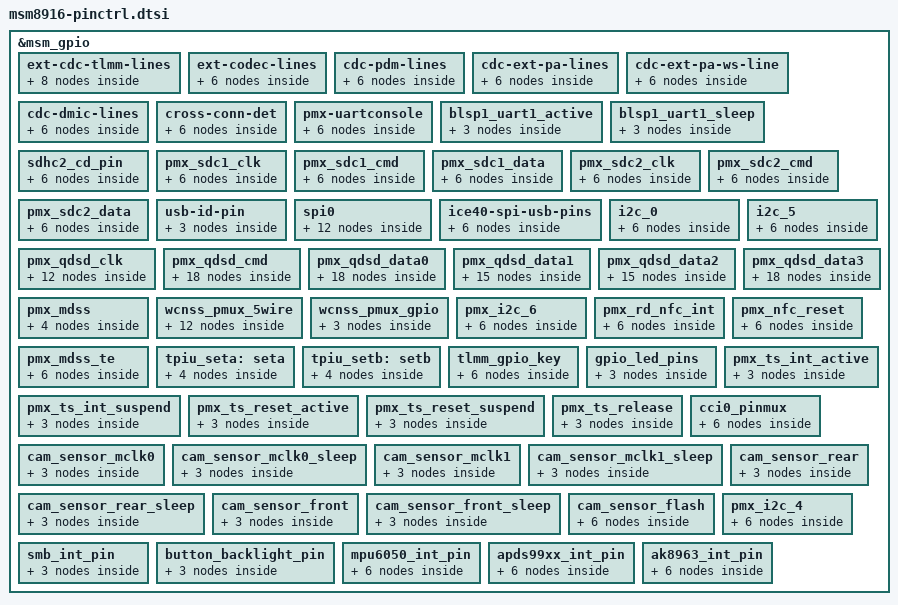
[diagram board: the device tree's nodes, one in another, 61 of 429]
/* Copyright (c) 2013-2014, The Linux Foundation. All rights reserved.
 *
 * This program is free software; you can redistribute it and/or modify
 * it under the terms of the GNU General Public License version 2 and
 * only version 2 as published by the Free Software Foundation.
 *
 * This program is distributed in the hope that it will be useful,
 * but WITHOUT ANY WARRANTY; without even the implied warranty of
 * MERCHANTABILITY or FITNESS FOR A PARTICULAR PURPOSE.  See the
 * GNU General Public License for more details.
 */

&msm_gpio {
	ext-cdc-tlmm-lines {
		ext_cdc_tlmm_lines_act: tlmm_lines_on {
			pinmux_pri {
				function = "pri_mi2s";
				pins = "gpio116";
			};
			pinmux_sec {
				function = "sec_mi2s";
				pins = "gpio112", "gpio117", "gpio118",
				       "gpio119";
			};
			pinconf {
				pins = "gpio112", "gpio116", "gpio117",
				       "gpio118", "gpio119";
				drive-strength = <8>;
				bias-pull-none;
			};
		};
		ext_cdc_tlmm_lines_sus: tlmm_lines_off {
			pinmux_pri {
				function = "pri_mi2s";
				pins = "gpio116";
			};
			pinmux_sec {
				function = "sec_mi2s";
				pins = "gpio112", "gpio117", "gpio118",
				       "gpio119";
			};
			pinconf {
				pins = "gpio112", "gpio116", "gpio117",
				       "gpio118", "gpio119";
				drive-strength = <2>;
				bias-disable;
			};
		};
	};

	ext-codec-lines {
		ext_codec_lines_act: lines_on {
			pinmux {
				function = "gpio";
				pins = "gpio67";
			};
			pinconf {
				pins = "gpio67";
				drive-strength = <8>;
				bias-disable;
				output-high;
			};
		};
		ext_codec_lines_sus: lines_off {
			pinmux {
				function = "gpio";
				pins = "gpio67";
			};
			pinconf {
				pins = "gpio67";
				drive-strength = <2>;
				bias-disable;
			};
		};
	};

	cdc-pdm-lines {
		cdc_pdm_lines_act: pdm_lines_on {
			pinmux {
				function = "cdc_pdm0";
				pins = "gpio63", "gpio64", "gpio65", "gpio66",
				       "gpio67", "gpio68";
			};
			pinconf {
				pins = "gpio63", "gpio64", "gpio65", "gpio66",
				       "gpio67", "gpio68";
				drive-strength = <8>;
				bias-pull-none;
			};
		};
		cdc_pdm_lines_sus: pdm_lines_off {
			pinmux {
				function = "cdc_pdm0";
				pins = "gpio63", "gpio64", "gpio65", "gpio66",
				       "gpio67", "gpio68";
			};
			pinconf {
				pins = "gpio63", "gpio64", "gpio65", "gpio66",
				       "gpio67", "gpio68";
				drive-strength = <2>;
				bias-disable;
			};
		};
	};

	cdc-ext-pa-lines {
		cdc_ext_pa_act: ext_pa_on {
			pinmux {
				function = "pri_mi2s";
				pins = "gpio113", "gpio114", "gpio115",
				       "gpio116";
			};
			pinconf {
				pins = "gpio113", "gpio114", "gpio115",
				       "gpio116";
				drive-strength = <8>;
				bias-pull-none;
			};
		};
		cdc_ext_pa_sus: ext_pa_off {
			pinmux {
				function = "pri_mi2s";
				pins = "gpio113", "gpio114", "gpio115",
				       "gpio116";
			};
			pinconf {
				pins = "gpio113", "gpio114", "gpio115",
				       "gpio116";
				drive-strength = <2>;
				bias-disable;
			};
		};
	};

	cdc-ext-pa-ws-line {
		cdc_ext_pa_ws_act: ext_pa_on {
			pinmux {
				function = "pri_mi2s_ws";
				pins = "gpio110";
			};
			pinconf {
				pins = "gpio110";
				drive-strength = <8>;
				bias-pull-none;
			};
		};
		cdc_ext_pa_ws_sus: ext_pa_off {
			pinmux {
				function = "pri_mi2s_ws";
				pins = "gpio110";
			};
			pinconf {
				pins = "gpio110";
				drive-strength = <2>;
				bias-disable;
			};
		};
	};

	cdc-dmic-lines {
		cdc_dmic_lines_act: dmic_lines_on {
			pinmux_dmic0_clk {
				function = "dmic0_clk";
				pins = "gpio0";
			};
			pinmux_dmic0_data {
				function = "dmic0_data";
				pins = "gpio1";
			};
			pinconf {
				pins = "gpio0", "gpio1";
				drive-strength = <8>;
			};
		};
		cdc_dmic_lines_sus: dmic_lines_off {
			pinconf {
				pins = "gpio0", "gpio1";
				drive-strength = <2>;
				bias-disable;
			};
		};
	};

	cross-conn-det {
		cross_conn_det_act: lines_on {
			pinmux {
				function = "gpio";
				pins = "gpio120";
			};
			pinconf {
				pins = "gpio120";
				drive-strength = <8>;
				output-low;
				bias-pull-down;
			};
		};
		cross_conn_det_sus: lines_off {
			pinmux {
				function = "gpio";
				pins = "gpio120";
			};
			pinconf {
				pins = "gpio120";
				drive-strength = <2>;
				bias-disable;
			};
		};
	};

	pmx-uartconsole {
		uart_console_default: default {
			pinmux {
				function = "blsp_uart2";
				pins = "gpio4", "gpio5";
			};
			pinconf {
				pins = "gpio4", "gpio5";
				drive-strength = <16>;
				bias-disable;
			};
		};
		uart_console_sleep: uart-console {
			pinmux {
				function = "blsp_uart2";
				pins = "gpio4", "gpio5";
			};
			pinconf {
				pins = "gpio4", "gpio5";
				drive-strength = <2>;
				bias-pull-down;
			};
		};
	};

	blsp1_uart1_active {
		hsuart_active: default {
			pinmux {
				function = "blsp_uart1";
				pins = "gpio0", "gpio1", "gpio2", "gpio3";
			};
			pinconf {
				pins = "gpio0", "gpio1", "gpio2", "gpio3";
				drive-strength = <16>;
				bias-disable;
			};
		};
	};

	blsp1_uart1_sleep {
		hsuart_sleep: sleep {
			pinmux {
				function = "blsp_uart1";
				pins = "gpio0", "gpio1", "gpio2", "gpio3";
			};
			pinconf {
				pins = "gpio0", "gpio1", "gpio2", "gpio3";
				drive-strength = <2>;
				bias-disable;
			};
		};
	};

	sdhc2_cd_pin {
		sdc2_cd_on: cd_on {
			pinmux {
				function = "gpio";
				pins = "gpio38";
			};
			pinconf {
				pins = "gpio38";
				drive-strength = <2>;
				bias-pull-up;
			};
		};
		sdc2_cd_off: cd_off {
			pinmux {
				function = "gpio";
				pins = "gpio38";
			};
			pinconf {
				pins = "gpio38";
				drive-strength = <2>;
				bias-disable;
			};
		};
	};

	pmx_sdc1_clk {
		sdc1_clk_on: clk_on {
			pinmux {
				pins = "sdc1_clk";
			};
			pinconf {
				pins = "sdc1_clk";
				bias-disable;
				drive-strength = <16>;
			};
		};
		sdc1_clk_off: clk_off {
			pinmux {
				pins = "sdc1_clk";
			};
			pinconf {
				pins = "sdc1_clk";
				bias-disable;
				drive-strength = <2>;
			};
		};
	};

	pmx_sdc1_cmd {
		sdc1_cmd_on: cmd_on {
			pinmux {
				pins = "sdc1_cmd";
			};
			pinconf {
				pins = "sdc1_cmd";
				bias-pull-up;
				drive-strength = <10>;
			};
		};
		sdc1_cmd_off: cmd_off {
			pinmux {
				pins = "sdc1_cmd";
			};
			pinconf {
				pins = "sdc1_cmd";
				bias-pull-up;
				drive-strength = <2>;
			};
		};
	};

	pmx_sdc1_data {
		sdc1_data_on: data_on {
			pinmux {
				pins = "sdc1_data";
			};
			pinconf {
				pins = "sdc1_data";
				bias-pull-up;
				drive-strength = <10>;
			};
		};
		sdc1_data_off: data_off {
			pinmux {
				pins = "sdc1_data";
			};
			pinconf {
				pins = "sdc1_data";
				bias-pull-up;
				drive-strength = <2>;
			};
		};
	};

	pmx_sdc2_clk {
		sdc2_clk_on: clk_on {
			pinmux {
				pins = "sdc2_clk";
			};
			pinconf {
				pins = "sdc2_clk";
				bias-disable;
				drive-strength = <16>;
			};
		};
		sdc2_clk_off: clk_off {
			pinmux {
				pins = "sdc2_clk";
			};
			pinconf {
				pins = "sdc2_clk";
				bias-disable;
				drive-strength = <2>;
			};
		};
	};

	pmx_sdc2_cmd {
		sdc2_cmd_on: cmd_on {
			pinmux {
				pins = "sdc2_cmd";
			};
			pinconf {
				pins = "sdc2_cmd";
				bias-pull-up;
				drive-strength = <10>;
			};
		};
		sdc2_cmd_off: cmd_off {
			pinmux {
				pins = "sdc2_cmd";
			};
			pinconf {
				pins = "sdc2_cmd";
				bias-pull-up;
				drive-strength = <2>;
			};
		};
	};

	pmx_sdc2_data {
		sdc2_data_on: data_on {
			pinmux {
				pins = "sdc2_data";
			};
			pinconf {
				pins = "sdc2_data";
				bias-pull-up;
				drive-strength = <10>;
			};
		};
		sdc2_data_off: data_off {
			pinmux {
				pins = "sdc2_data";
			};
			pinconf {
				pins = "sdc2_data";
				bias-pull-up;
				drive-strength = <2>;
			};
		};
	};

	usb-id-pin {
		usbid_default: default {
			pinmux {
				function = "gpio";
				pins = "gpio110";
			};
			pinconf {
				pins = "gpio110";
				drive-strength = <8>;
				bias-pull-up;
			};
		};
	};

	spi0 {
		/* MOSI, MISO, CLK */
		spi0_default: default {
			pinmux {
				function = "blsp_spi3";
				pins = "gpio8", "gpio9", "gpio11";
			};
			pinconf {
				pins = "gpio8", "gpio9", "gpio11";
				drive-strength = <12>;
				bias-disable = <0>;
			};
		};

		spi0_sleep: sleep {
			pinmux {
				function = "gpio";
				pins = "gpio8", "gpio9", "gpio11";
			};
			pinconf {
				pins = "gpio8", "gpio9", "gpio11";
				drive-strength = <2>;
				bias-pull-down;
			};
		};

		/* CS */
		spi0_cs0_active: cs0_active {
			pinmux {
				function = "blsp_spi3";
				pins = "gpio10";
			};
			pinconf {
				pins = "gpio10";
				drive-strength = <2>;
				bias-disable = <0>;
			};
		};

		spi0_cs0_sleep: cs0_sleep {
			pinmux {
				function = "gpio";
				pins = "gpio10";
			};
			pinconf {
				pins = "gpio10";
				drive-strength = <2>;
				bias-disable = <0>;
			};
		};
	};

	ice40-spi-usb-pins {
		ice40_default: default {
			pinmux {
				function = "gpio";
				pins = "gpio0", "gpio1", "gpio3", "gpio114";
			};
			pinconf {
				pins = "gpio0", "gpio1", "gpio3", "gpio114";
				drive-strength = <8>;
				bias-disable;
			};
		};

		ice40_sleep: sleep {
			pinmux {
				function = "gpio";
				pins = "gpio0", "gpio1", "gpio3", "gpio114";
			};
			pinconf {
				pins = "gpio0", "gpio1", "gpio3", "gpio114";
				drive-strength = <2>;
				bias-pull-down;
			};
		};
	};

	i2c_0 {
		/* CLK, DATA */
		i2c_0_active: i2c_0_active {
			pinmux {
				function = "blsp_i2c2";
				pins = "gpio6", "gpio7";
			};
			pinconf {
				pins = "gpio6", "gpio7";
				drive-strength = <2>;
				bias-disable;
			};
		};

		i2c_0_sleep: i2c_0_sleep {
			pinmux {
				function = "blsp_i2c2";
				pins = "gpio6", "gpio7";
			};
			pinconf {
				pins = "gpio6", "gpio7";
				drive-strength = <2>;
				bias-disable;
			};
		};
	};

	i2c_5 {
		/* CLK, DATA */
		i2c_5_active: i2c_5_active {
			pinmux {
				function = "blsp_i2c5";
				pins = "gpio18", "gpio19";
			};
			pinconf {
				pins = "gpio18", "gpio19";
				drive-strength = <2>;
				bias-disable = <0>;
			};
		};

		i2c_5_sleep: i2c_5_sleep {
			pinmux {
				function = "blsp_i2c5";
				pins = "gpio18", "gpio19";
			};
			pinconf {
				pins = "gpio18", "gpio19";
				drive-strength = <2>;
				bias-disable = <0>;
			};
		};
	};

	pmx_qdsd_clk {
		qdsd_clk_sdcard: clk_sdcard {
			pinmux {
				pins = "qdsd_clk";
			};
			pinconf {
				pins = "qdsd_clk";
				bias-disable;
				drive-strength = <7>;
			};
		};
		qdsd_clk_trace: clk_trace {
			pinmux {
				pins = "qdsd_clk";
			};
			pinconf {
				pins = "qdsd_clk";
				bias-pull-down;
				drive-strength = <0>;
			};
		};
		qdsd_clk_swdtrc: clk_swdtrc {
			pinmux {
				pins = "qdsd_clk";
			};
			pinconf {
				pins = "qdsd_clk";
				bias-pull-down;
				drive-strength = <0>;
			};
		};
		qdsd_clk_spmi: clk_spmi {
			pinmux {
				pins = "qdsd_clk";
			};
			pinconf {
				pins = "qdsd_clk";
				bias-pull-down;
				drive-strength = <0>;
			};
		};
	};

	pmx_qdsd_cmd {
		qdsd_cmd_sdcard: cmd_sdcard {
			pinmux {
				pins = "qdsd_cmd";
			};
			pinconf {
				pins = "qdsd_cmd";
				bias-pull-down;
				drive-strength = <3>;
			};
		};
		qdsd_cmd_trace: cmd_trace {
			pinmux {
				pins = "qdsd_cmd";
			};
			pinconf {
				pins = "qdsd_cmd";
				bias-pull-down;
				drive-strength = <0>;
			};
		};
		qdsd_cmd_swduart: cmd_uart {
			pinmux {
				pins = "qdsd_cmd";
			};
			pinconf {
				pins = "qdsd_cmd";
				bias-pull-up;
				drive-strength = <0>;
			};
		};
		qdsd_cmd_swdtrc: cmd_swdtrc {
			pinmux {
				pins = "qdsd_cmd";
			};
			pinconf {
				pins = "qdsd_cmd";
				bias-pull-up;
				drive-strength = <0>;
			};
		};
		qdsd_cmd_jtag: cmd_jtag {
			pinmux {
				pins = "qdsd_cmd";
			};
			pinconf {
				pins = "qdsd_cmd";
				bias-disable;
				drive-strength = <3>;
			};
		};
		qdsd_cmd_spmi: cmd_spmi {
			pinmux {
				pins = "qdsd_cmd";
			};
			pinconf {
				pins = "qdsd_cmd";
				bias-pull-down;
				drive-strength = <4>;
			};
		};
	};

	pmx_qdsd_data0 {
		qdsd_data0_sdcard: data0_sdcard {
			pinmux {
				pins = "qdsd_data0";
			};
			pinconf {
				pins = "qdsd_data0";
				bias-pull-down;
				drive-strength = <3>;
			};
		};
		qdsd_data0_trace: data0_trace {
			pinmux {
				pins = "qdsd_data0";
			};
			pinconf {
				pins = "qdsd_data0";
				bias-pull-down;
				drive-strength = <0>;
			};
		};
		qdsd_data0_swduart: data0_uart {
			pinmux {
				pins = "qdsd_data0";
			};
			pinconf {
				pins = "qdsd_data0";
				bias-pull-down;
				drive-strength = <0>;
			};
		};
		qdsd_data0_swdtrc: data0_swdtrc {
			pinmux {
				pins = "qdsd_data0";
			};
			pinconf {
				pins = "qdsd_data0";
				bias-pull-down;
				drive-strength = <0>;
			};
		};
		qdsd_data0_jtag: data0_jtag {
			pinmux {
				pins = "qdsd_data0";
			};
			pinconf {
				pins = "qdsd_data0";
				bias-pull-up;
				drive-strength = <0>;
			};
		};
		qdsd_data0_spmi: data0_spmi {
			pinmux {
				pins = "qdsd_data0";
			};
			pinconf {
				pins = "qdsd_data0";
				bias-pull-down;
				drive-strength = <0>;
			};
		};
	};

	pmx_qdsd_data1 {
		qdsd_data1_sdcard: data1_sdcard {
			pinmux {
				pins = "qdsd_data1";
			};
			pinconf {
				pins = "qdsd_data1";
				bias-pull-down;
				drive-strength = <3>;
			};
		};
		qdsd_data1_trace: data1_trace {
			pinmux {
				pins = "qdsd_data1";
			};
			pinconf {
				pins = "qdsd_data1";
				bias-pull-down;
				drive-strength = <3>;
			};
		};
		qdsd_data1_swduart: data1_uart {
			pinmux {
				pins = "qdsd_data1";
			};
			pinconf {
				pins = "qdsd_data1";
				bias-pull-down;
				drive-strength = <0>;
			};
		};
		qdsd_data1_swdtrc: data1_swdtrc {
			pinmux {
				pins = "qdsd_data1";
			};
			pinconf {
				pins = "qdsd_data1";
				bias-pull-down;
				drive-strength = <0>;
			};
		};
		qdsd_data1_jtag: data1_jtag {
			pinmux {
				pins = "qdsd_data1";
			};
			pinconf {
				pins = "qdsd_data1";
				bias-pull-down;
				drive-strength = <0>;
			};
		};
	};

	pmx_qdsd_data2 {
		qdsd_data2_sdcard: data2_sdcard {
			pinmux {
				pins = "qdsd_data2";
			};
			pinconf {
				pins = "qdsd_data2";
				bias-pull-down;
				drive-strength = <3>;
			};
		};
		qdsd_data2_trace: data2_trace {
			pinmux {
				pins = "qdsd_data2";
			};
			pinconf {
				pins = "qdsd_data2";
				bias-pull-down;
				drive-strength = <3>;
			};
		};
		qdsd_data2_swduart: data2_uart {
			pinmux {
				pins = "qdsd_data2";
			};
			pinconf {
				pins = "qdsd_data2";
				bias-pull-down;
				drive-strength = <0>;
			};
		};
		qdsd_data2_swdtrc: data2_swdtrc {
			pinmux {
				pins = "qdsd_data2";
			};
			pinconf {
				pins = "qdsd_data2";
				bias-pull-down;
				drive-strength = <0>;
			};
		};
		qdsd_data2_jtag: data2_jtag {
			pinmux {
				pins = "qdsd_data2";
			};
			pinconf {
				pins = "qdsd_data2";
				bias-pull-up;
				drive-strength = <3>;
			};
		};
	};

	pmx_qdsd_data3 {
		qdsd_data3_sdcard: data3_sdcard {
			pinmux {
				pins = "qdsd_data3";
			};
			pinconf {
				pins = "qdsd_data3";
				bias-pull-down;
				drive-strength = <3>;
			};
		};
		qdsd_data3_trace: data3_trace {
			pinmux {
				pins = "qdsd_data3";
			};
			pinconf {
				pins = "qdsd_data3";
				bias-pull-down;
				drive-strength = <3>;
			};
		};
		qdsd_data3_swduart: data3_uart {
			pinmux {
				pins = "qdsd_data3";
			};
			pinconf {
				pins = "qdsd_data3";
				bias-pull-up;
				drive-strength = <0>;
			};
		};
		qdsd_data3_swdtrc: data3_swdtrc {
			pinmux {
				pins = "qdsd_data3";
			};
			pinconf {
				pins = "qdsd_data3";
				bias-pull-up;
				drive-strength = <0>;
			};
		};
		qdsd_data3_jtag: data3_jtag {
			pinmux {
				pins = "qdsd_data3";
			};
			pinconf {
				pins = "qdsd_data3";
				bias-pull-up;
				drive-strength = <0>;
			};
		};
		qdsd_data3_spmi: data3_spmi {
			pinmux {
				pins = "qdsd_data3";
			};
			pinconf {
				pins = "qdsd_data3";
				bias-pull-down;
				drive-strength = <3>;
			};
		};
	};

	pmx_mdss {
		mdss_dsi_active: active {
			pinconf {
				drive-strength = <8>;
				bias-disable = <0>;
				output-high;
			};
		};
		mdss_dsi_suspend: suspend {
			pinconf {
				drive-strength = <2>;
				bias-pull-down;
				output-low;
			};
		};
	};

	wcnss_pmux_5wire: wcnss_pmux_5wire {
		wcnss_default: wcnss_default {
			pinmux2 {
				function = "wcss_wlan2";
				pins = "gpio40";
			};
			pinmux1 {
				function = "wcss_wlan1";
				pins = "gpio41";
			};
			pinmux0 {
				function = "wcss_wlan0";
				pins = "gpio42";
			};
			pinmux {
				function = "wcss_wlan";
				pins = "gpio43", "gpio44";
			};
			pinconf {
				pins = "gpio40", "gpio41", "gpio42", "gpio43",
				       "gpio44";
				drive-strength = <6>;
				bias-pull-up;
			};
		};

		wcnss_sleep: wcnss_sleep {
			pinmux2 {
				function = "wcss_wlan2";
				pins = "gpio40";
			};
			pinmux1 {
				function = "wcss_wlan1";
				pins = "gpio41";
			};
			pinmux0 {
				function = "wcss_wlan0";
				pins = "gpio42";
			};
			pinmux {
				function = "wcss_wlan";
				pins = "gpio43", "gpio44";
			};
			pinconf {
				pins = "gpio40", "gpio41", "gpio42", "gpio43",
				       "gpio44";
				drive-strength = <2>;
				bias-pull-down;
			};
		};
	};

	wcnss_pmux_gpio: wcnss_pmux_gpio {
		wcnss_gpio_default: wcnss_gpio_default {
			pinmux {
				function = "gpio";
				pins = "gpio40", "gpio41", "gpio42", "gpio43",
				       "gpio44";
			};
			pinconf {
				pins = "gpio40", "gpio41", "gpio42", "gpio43",
				       "gpio44";
				drive-strength = <6>;
				bias-pull-up;
			};
		};
	};

	pmx_i2c_6 {
		/* CLK, DATA */
		i2c_6_active: i2c_6_active{
			pinmux {
				function = "blsp_i2c6";
				pins = "gpio22", "gpio23";
			};
			pinconf {
				pins = "gpio22", "gpio23";
				drive-strength = <2>;
				bias-disable;
			};
		};

		i2c_6_sleep: i2c_6_sleep {
			pinmux {
				function = "blsp_i2c6";
				pins = "gpio22", "gpio23";
			};
			pinconf {
				pins = "gpio22", "gpio23";
				drive-strength = <2>;
				bias-disable;
			};
		};
	};

	pmx_rd_nfc_int{
		nfc_int_active: active {
			pinmux {
				function = "gpio";
				pins = "gpio21";
			};
			pinconf {
				pins = "gpio21";
				drive-strength = <6>;
				bias-pull-up;
			};
		};

		nfc_int_suspend: suspend {
			pinmux {
				function = "gpio";
				pins = "gpio21";
			};
			pinconf {
				pins = "gpio21";
				drive-strength = <6>;
				bias-pull-up;
			};
		};
	};

	pmx_nfc_reset{
		nfc_disable_active: active {
			pinmux {
				function = "gpio";
				pins = "gpio20";
			};
			pinconf {
				pins = "gpio20";
				drive-strength = <6>;
				bias-pull-up;
			};
		};

		nfc_disable_suspend: suspend {
			pinmux {
				function = "gpio";
				pins = "gpio20";
			};
			pinconf {
				pins = "gpio20";
				drive-strength = <6>;
				bias-disable;
			};
		};
	};

	pmx_mdss_te: pmx_mdss_te {
		mdss_te_active: active {
			pinmux {
				function = "mdp_vsync";
				pins = "gpio24";
			};
			pinconf {
				pins = "gpio24";
				drive-strength = <2>;
				bias-pull-down;
				input-debounce = <0>;
			};
		};

		mdss_te_suspend: suspend {
			pinmux {
				function = "mdp_vsync";
				pins = "gpio24";
			};
			pinconf {
				pins = "gpio24";
				drive-strength = <2>;
				bias-pull-down;
				input-debounce = <0>;
			};
		};
	};

	/* CoreSight */
	tpiu_seta: seta {
		pinmux_data {
			function = "qdss_tracedata_a";
			pins = "gpio8", "gpio9", "gpio10", "gpio39", "gpio40",
			       "gpio41", "gpio42", "gpio43", "gpio47", "gpio48",
			       "gpio62", "gpio69", "gpio112", "gpio113", "gpio114",
			       "gpio115";
		};
		pinmux_ctl {
			function = "qdss_tracectl_a";
			pins = "gpio45";
		};
		pinmux_clk {
			function = "qdss_traceclk_a";
			pins = "gpio46";
		};
		pinconf {
			pins = "gpio8", "gpio9", "gpio10", "gpio39", "gpio40",
			       "gpio41", "gpio42", "gpio43", "gpio45", "gpio46",
			       "gpio47", "gpio48", "gpio62", "gpio69", "gpio112",
			       "gpio113", "gpio114", "gpio115";
			drive-strength = <16>;
			bias-disable;
		};
	};

	tpiu_setb: setb {
		pinmux_data {
			function = "qdss_tracedata_b";
			pins = "gpio26", "gpio27", "gpio28", "gpio29", "gpio30",
			       "gpio31", "gpio32", "gpio33", "gpio34", "gpio35",
			       "gpio36", "gpio37", "gpio110", "gpio111", "gpio120",
			       "gpio121";
		};
		pinmux_ctl {
			function = "qdss_tracectl_b";
			pins = "gpio4";
		};
		pinmux_clk {
			function = "qdss_traceclk_b";
			pins = "gpio5";
		};
		pinconf {
			pins = "gpio4", "gpio5", "gpio26", "gpio27", "gpio28",
			       "gpio29", "gpio30", "gpio31", "gpio32", "gpio33",
			       "gpio34", "gpio35", "gpio36", "gpio37", "gpio110",
			       "gpio111", "gpio120", "gpio121";
			drive-strength = <16>;
			bias-disable;
		};
	};

	tlmm_gpio_key {
		gpio_key_active: gpio_key_active {
			pinmux {
				function = "gpio";
				pins = "gpio107", "gpio108", "gpio109";
			};
			pinconf {
				pins = "gpio107", "gpio108", "gpio109";
				drive-strength = <2>;
				bias-pull-up;
			};
		};
		gpio_key_suspend: gpio_key_suspend {
			pinmux {
				function = "gpio";
				pins = "gpio107", "gpio108", "gpio109";
			};
			pinconf {
				pins = "gpio107", "gpio108", "gpio109";
				drive-strength = <2>;
				bias-pull-up;
			};
		};
	};

	gpio_led_pins {
		gpio_led_off: led_off {
			pinmux {
				function = "gpio";
				pins = "gpio8", "gpio9", "gpio10";
			};
			pinconf {
				pins = "gpio8", "gpio9", "gpio10";
				drive-strength = <2>;
				bias-disable;
				output-low;
			};
		};
	};

	/* add pingrp for touchscreen */
	pmx_ts_int_active {
		ts_int_active: ts_int_active {
			pinmux {
				function = "gpio";
				pins = "gpio13";
			};
			pinconf {
				pins = "gpio13";
				drive-strength = <16>;
				bias-pull-up;
			};
		};
	};

	pmx_ts_int_suspend {
		ts_int_suspend: ts_int_suspend {
			pinmux {
				function = "gpio";
				pins = "gpio13";
			};
			pinconf {
				pins = "gpio13";
				drive-strength = <2>;
				bias-pull-down;
			};
		};
	};

	pmx_ts_reset_active {
		ts_reset_active: ts_reset_active {
			pinmux {
				finction = "gpio";
				pins = "gpio12";
			};
			pinconf {
				pins = "gpio12";
				drive-strength = <16>;
				bias-pull-up;
			};
		};
	};

	pmx_ts_reset_suspend {
		ts_reset_suspend: ts_reset_suspend {
			pinmux {
				function = "gpio";
				pins = "gpio12";
			};
			pinconf {
				pins = "gpio12";
				drive-strength = <2>;
				bias-pull-down;
			};
		};
	};

	pmx_ts_release {
		ts_release: ts_release {
			pinmux {
				function = "gpio";
				pins = "gpio12", "gpio13";
			};
			pinconf {
				pins = "gpio12", "gpio13";
				drive-strength = <2>;
				bias-pull-down;
			};
		};
	};

	cci0_pinmux {
		/* CLK, DATA */
		cci0_default: default {
			pinmux {
				function = "cci_i2c";
				pins = "gpio29", "gpio30";
			};
			pinconf {
				pins = "gpio29", "gpio30";
				drive-strength = <2>;
				bias-disable = <0>;
			};
		};
		cci0_sleep: sleep {
			pinmux {
				function = "cci_i2c";
				pins = "gpio29", "gpio30";
			};
			pinconf {
				pins = "gpio29", "gpio30";
				drive-strength = <2>;
				bias-disable = <0>;
			};
		};
	};

	cam_sensor_mclk0 {
		/* MCLK */
		cam_sensor_mclk0_default: default {
			pinmux {
				function = "cam_mclk";
				pins = "gpio26";
			};
			pinconf {
				pins = "gpio26";
				drive-strength = <2>;
				bias-disable = <0>;
			};
		};
	};

	cam_sensor_mclk0_sleep {
		/* MCLK */
		cam_sensor_mclk0_sleep: sleep {
			pinmux {
				function = "cam_mclk";
				pins = "gpio26";
			};
			pinconf {
				pins = "gpio26";
				drive-strength = <2>;
				bias-pull-down;
			};
		};
	};

	cam_sensor_mclk1 {
		/* MCLK */
		cam_sensor_mclk1_default: default {
			pinmux {
				function = "cam_mclk";
				pins = "gpio27";
			};
			pinconf {
				pins = "gpio27";
				drive-strength = <2>;
				bias-disable = <0>;
			};
		};
	};

	cam_sensor_mclk1_sleep {
		/* MCLK */
		cam_sensor_mclk1_sleep: sleep {
			pinmux {
				function = "cam_mclk";
				pins = "gpio27";
			};
			pinconf {
				pins = "gpio27";
				drive-strength = <2>;
				bias-pull-down;
			};
		};
	};

	cam_sensor_rear {
		/* RESET, STANDBY */
		cam_sensor_rear_default: default {
			pinmux {
				function = "gpio";
				pins = "gpio34", "gpio35";
			};
			pinconf {
				pins = "gpio34", "gpio35";
				drive-strength = <2>;
				bias-disable = <0>;
			};
		};
	};

	cam_sensor_rear_sleep {
		/* RESET, STANDBY */
		cam_sensor_rear_sleep: sleep {
			pinmux {
				function = "gpio";
				pins = "gpio34", "gpio35";
			};
			pinconf {
				pins = "gpio34", "gpio35";
				drive-strength = <2>;
				bias-pull-down;
			};
		};
	};

	cam_sensor_front {
		/* RESET, STANDBY */
		cam_sensor_front_default: default {
			pinmux {
				function = "gpio";
				pins = "gpio28", "gpio33";
			};
			pinconf {
				pins = "gpio28", "gpio33";
				drive-strength = <2>;
				bias-disable = <0>;
			};
		};
	};

	cam_sensor_front_sleep {
		/* RESET, STANDBY */
		cam_sensor_front_sleep: sleep {
			pinmux {
				function = "gpio";
				pins = "gpio28", "gpio33";
			};
			pinconf {
				pins = "gpio28", "gpio33";
				drive-strength = <2>;
				bias-pull-down = <0>;
			};
		};
	};

	cam_sensor_flash {
		/* FLASH_RESET,FLASH_EN,FLASH_NOW */
		cam_sensor_flash_default: default {
			pinmux {
				function = "gpio";
				pins = "gpio31", "gpio32", "gpio36";
			};
			pinconf {
				pins = "gpio31", "gpio32", "gpio36";
				drive-strength = <2>;
				bias-disable = <0>;
			};
		};

		cam_sensor_flash_sleep: sleep {
			pinmux {
				function = "gpio";
				pins = "gpio31", "gpio32", "gpio36";
			};
			pinconf {
				pins = "gpio31", "gpio32", "gpio36";
				drive-strength = <2>;
				bias-pull-down = <0>;
			};
		};
	};

	pmx_i2c_4 {
		/* CLK, DATA */
		i2c_4_active: i2c_4_active {
			pinmux {
				function = "blsp_i2c4";
				pins = "gpio14", "gpio15";
			};
			pinconf {
				pins = "gpio14", "gpio15";
				drive-strength = <2>;
				bias-disable = <0>;
			};
		};

		i2c_4_sleep: i2c_4_sleep {
			pinmux {
				function = "blsp_i2c4";
				pins = "gpio14", "gpio15";
			};
			pinconf {
				pins = "gpio14", "gpio15";
				drive-strength = <2>;
				bias-disable = <0>;
			};
		};
	};

	smb_int_pin {
		smb_int_default: smb_int_default {
			pinmux {
				function = "gpio";
				pins = "gpio62";
			};
			pinconf {
				pins = "gpio62";
				drive-strength = <2>;
				bias-pull-up;
			};
		};
	};

	button_backlight_pin {
		button_backlight_off: button_backlight_off {
			pinmux {
				function = "gpio";
				pins = "gpio119";
			};
			pinconf {
				pins = "gpio119";
				drive-strength = <2>;
				bias-disable;
				output-low;
			};
		};
	};

	mpu6050_int_pin {
		mpu6050_default: mpu6050_default {
			pinmux {
				function = "gpio";
				pins = "gpio115";
			};
			pinconf {
				pins = "gpio115";
				drive-strength = <6>;
				bias-pull-up;
			};
		};
		mpu6050_sleep: mpu6050_sleep {
			pinmux {
				function = "gpio";
				pins = "gpio115";
			};
			pinconf {
				pins = "gpio115";
				drive-strength = <2>;
			};
		};
	};

	apds99xx_int_pin {
		apds99xx_default: apds99xx_default {
			pinmux {
				function = "gpio";
				pins = "gpio113";
			};
			pinconf {
				pins = "gpio113";
				drive-strength = <6>;
				bias-pull-up;
			};
		};
		apds99xx_sleep: apds99xx_sleep {
			pinmux {
				function = "gpio";
				pins = "gpio113";
			};
			pinconf {
				pins = "gpio113";
				drive-strength = <2>;
				bias-pull-down;
			};
		};
	};

	ak8963_int_pin {
		ak8963_default: ak8963_default {
			pinmux {
				function = "gpio";
				pins = "gpio69";
			};
			pinconf {
				pins = "gpio69";
				drive-strength = <6>;
				bias-pull-up;
			};
		};
		ak8963_sleep: ak8963_sleep {
			pinmux {
				function = "gpio";
				pins = "gpio69";
			};
			pinconf {
				pins = "gpio69";
				drive-strength = <2>;
				bias-pull-down;
			};
		};
	};
};
